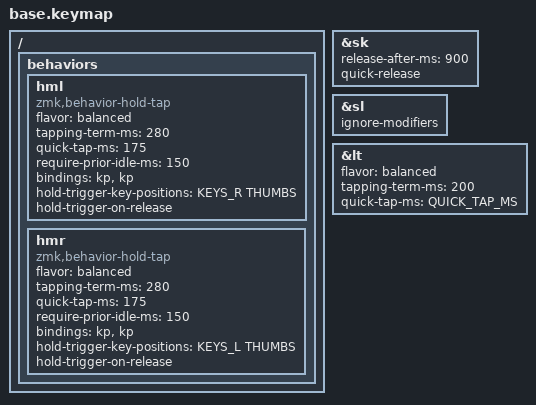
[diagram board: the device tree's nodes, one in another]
#include <behaviors.dtsi>
#include <dt-bindings/zmk/keys.h>
#include <input/processors.dtsi>
#include <zephyr/dt-bindings/input/input-event-codes.h>

#include <dt-bindings/zmk/bt.h>
#include <dt-bindings/zmk/outputs.h>
#define _BT_SEL_KEYS_                                                        \
    &bt BT_SEL 0 &bt BT_SEL 1 &bt BT_SEL 2 &bt BT_SEL 3 &bt BT_CLR

#include <dt-bindings/zmk/ext_power.h>
#include <dt-bindings/zmk/rgb.h>


#include "zmk-helpers/helper.h"

#define DEF 0
#define NAV 1
#define FN 2
#define NUM 3
#define SYS 4
#define MOUSE 5

#define XXX &none
#define ___ &trans

/* Global defaults */

#define QUICK_TAP_MS 175

&sk {
  release-after-ms = <900>;
  quick-release;
};

&sl { // Allow sticky mods to chord across sticky layers.
  ignore-modifiers;
};

&lt {
  flavor = "balanced";
  tapping-term-ms = <200>;
  quick-tap-ms = <QUICK_TAP_MS>;
};

/* Homerow mods */

#define KEYS_L LT0 LT1 LT2 LT3 LT4 LM0 LM1 LM2 LM3 LM4 LB0 LB1 LB2 LB3 LB4
#define KEYS_R RT0 RT1 RT2 RT3 RT4 RM0 RM1 RM2 RM3 RM4 RB0 RB1 RB2 RB3 RB4

#define THUMBS LH2 LH1 LH0 RH0 RH1 RH2 // Thumbs on 36+ keys.


/* Left-hand HRMs. */
ZMK_HOLD_TAP(hml,
    flavor = "balanced";
    tapping-term-ms = <280>;
    quick-tap-ms = <175>;
    require-prior-idle-ms = <150>;
    bindings = <&kp>, <&kp>;
    hold-trigger-key-positions = <KEYS_R THUMBS>;
    hold-trigger-on-release;
)

/* Right-hand HRMs. */
ZMK_HOLD_TAP(hmr,
    flavor = "balanced";
    tapping-term-ms = <280>;
    quick-tap-ms = <175>;
    require-prior-idle-ms = <150>;
    bindings = <&kp>, <&kp>;
    hold-trigger-key-positions = <KEYS_L THUMBS>;
    hold-trigger-on-release;
)


/* Keymap */

#define kBKSLASH NON_US_BACKSLASH


ZMK_BASE_LAYER(Qwerty,
// ╭───────────────┬───────────────┬───────────────┬───────────────┬───────────────┬───────────────╮          ╭───────────────┬───────────────┬───────────────┬───────────────┬───────────────┬───────────────╮
    &kp GRAVE       &kp Q           &kp W           &kp E            &kp R          &kp T          ,           &kp Y           &kp U           &kp I           &kp O           &kp P           &kp LEFT_BRACKET,
// ├───────────────┼───────────────┼───────────────┼───────────────┼───────────────┼───────────────┤          ├───────────────┼───────────────┼───────────────┼───────────────┼───────────────┼───────────────┤
    &kp kBKSLASH    &kp A           &kp S           &kp D           &kp F          &kp G           ,           &kp H           &kp J           &kp K           &kp L           &kp SEMI        &kp RIGHT_BRACKET,
// ├───────────────┼───────────────┼───────────────┼───────────────┼───────────────┼───────────────┤          ├───────────────┼───────────────┼───────────────┼───────────────┼───────────────┼───────────────┤
    &kp MINUS       &hml LGUI Z     &hml LALT X     &hml LCTRL C    &hml LSHFT V    &kp B          ,           &kp N           &hmr RSHFT M    &hmr RCTRL COMMA &hmr LALT DOT  &hmr RGUI FSLH  &kp SQT        ,
// ╰───────────────┴───────────────┴───────────────┼───────────────┼───────────────┼───────────────┤          ├───────────────┼───────────────┼───────────────┼───────────────┴───────────────┴───────────────╯
                                                    &kp ESCAPE      &kp SPACE       &kp TAB        ,          &kp ENTER     &kp BACKSPACE &kp DELETE         ,
                                                 //╰───────────────┴───────────────┴───────────────╯          ╰───────────────┴───────────────┴───────────────╯
                                                  // ╭───────────────┬───────────────┬───────────────╮
                                                                       &kp UP                        ,
                                                  // ├───────────────┼───────────────┼───────────────┤
                                                      &kp LEFT         &kp ENTER         &kp RIGHT   ,
                                                  // ├───────────────┼───────────────┼───────────────┤
                                                      &kp SPACE         &kp DOWN                     ,
                                                  // ╰───────────────┴───────────────┴───────────────╯
&inc_dec_kp C_VOLUME_UP C_VOLUME_DOWN
)
/* vim: set ft=c tw=146: */
